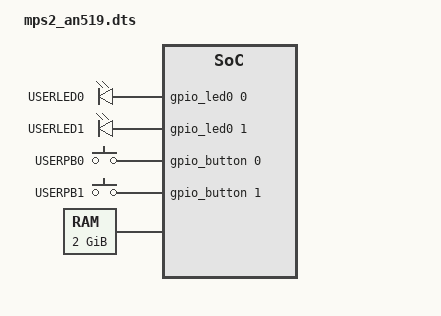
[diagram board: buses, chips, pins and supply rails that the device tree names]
/*
 * Copyright (c) 2018-2021 Linaro Limited
 *
 * SPDX-License-Identifier: Apache-2.0
 */

/dts-v1/;

#include <mem.h>
#include <arm/armv8-m.dtsi>
#include <dt-bindings/i2c/i2c.h>

/ {
	compatible = "arm,mps2";
	#address-cells = <1>;
	#size-cells = <1>;

	aliases {
		led0 = &led_0;
		led1 = &led_1;
		sw0 = &user_button_0;
		sw1 = &user_button_1;
	};

	chosen {
		zephyr,console = &uart0;
		zephyr,shell-uart = &uart0;
		zephyr,sram = &dtcm;
		zephyr,flash = &itcm;
	};

	leds {
		compatible = "gpio-leds";
		led_0: led_0 {
			gpios = <&gpio_led0 0>;
			label = "USERLED0";
		};
		led_1: led_1 {
			gpios = <&gpio_led0 1>;
			label = "USERLED1";
		};
	};

	gpio_keys {
		compatible = "gpio-keys";
		user_button_0: button_0 {
			label = "USERPB0";
			gpios = <&gpio_button 0>;
		};
		user_button_1: button_1 {
			label = "USERPB1";
			gpios = <&gpio_button 1>;
		};
	};

	cpus {
		#address-cells = <1>;
		#size-cells = <0>;

		cpu@0 {
			device_type = "cpu";
			compatible = "arm,cortex-m23";
			reg = <0>;
			#address-cells = <1>;
			#size-cells = <1>;

			mpu: mpu@e000ed90 {
				compatible = "arm,armv8m-mpu";
				reg = <0xe000ed90 0x40>;
				arm,num-mpu-regions = <8>;
			};
		};
	};

	/* We utilize the secure addresses, if you subtract 0x10000000
	 * you'll get the non-secure alias
	 */
	itcm: itcm@10000000 {	/* alias @ 0x0 */
		reg = <0x10000000 DT_SIZE_K(512)>;
	};

	sram: sram@11000000 {	/* alias @ 0x01000000 */
		compatible = "mmio-sram";
		reg = <0x11000000 DT_SIZE_M(2)>;
	};

	dtcm: dtcm@30000000 {	/* alias @ 0x20000000 */
		reg = <0x30000000 DT_SIZE_K(512)>;
	};

	isram: sram@31000000 {/* alias @ 0x21000000 */
		compatible = "mmio-sram";
		reg = <0x31000000 DT_SIZE_M(4)>;
	};

	/* DDR4 - 2G, alternates non-secure/secure every 256M */
	ddr4: memory@60000000 {
		device_type = "memory";
		reg = <0x60000000 DT_SIZE_M(256)
		       0x70000000 DT_SIZE_M(256)
		       0x80000000 DT_SIZE_M(256)
		       0x90000000 DT_SIZE_M(256)
		       0xa0000000 DT_SIZE_M(256)
		       0xb0000000 DT_SIZE_M(256)
		       0xc0000000 DT_SIZE_M(256)
		       0xd0000000 DT_SIZE_M(256)>;
	};

	soc {
		peripheral@50000000 {
			#address-cells = <1>;
			#size-cells = <1>;
			ranges = <0x0 0x50000000 0x10000000>;

			#include "mps2_an519-common.dtsi"
		};
	};
};

&nvic {
	arm,num-irq-priority-bits = <3>;
};
